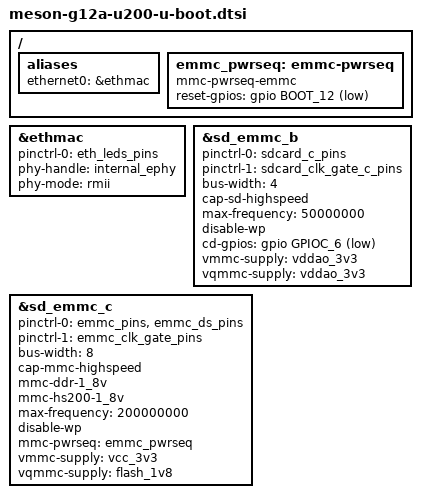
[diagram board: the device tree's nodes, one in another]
// SPDX-License-Identifier: (GPL-2.0+ OR MIT)
/*
 * Copyright (c) 2019 BayLibre, SAS.
 * Author: Neil Armstrong <narmstrong@baylibre.com>
 */

#include "meson-g12a-u-boot.dtsi"

 / {
	aliases {
		ethernet0 = &ethmac;
	};

	emmc_pwrseq: emmc-pwrseq {
		compatible = "mmc-pwrseq-emmc";
		reset-gpios = <&gpio BOOT_12 GPIO_ACTIVE_LOW>;
	};
};

&ethmac {
	status = "okay";
	pinctrl-0 = <&eth_leds_pins>;
	pinctrl-names = "default";
	phy-handle = <&internal_ephy>;
	phy-mode = "rmii";
};


/* SD card */
&sd_emmc_b {
	status = "okay";
	pinctrl-0 = <&sdcard_c_pins>;
	pinctrl-1 = <&sdcard_clk_gate_c_pins>;
	pinctrl-names = "default", "clk-gate";

	bus-width = <4>;
	cap-sd-highspeed;
	max-frequency = <50000000>;
	disable-wp;

	cd-gpios = <&gpio GPIOC_6 GPIO_ACTIVE_LOW>;
	vmmc-supply = <&vddao_3v3>;
	vqmmc-supply = <&vddao_3v3>;
};

/* eMMC */
&sd_emmc_c {
	status = "okay";
	pinctrl-0 = <&emmc_pins>, <&emmc_ds_pins>;
	pinctrl-1 = <&emmc_clk_gate_pins>;
	pinctrl-names = "default", "clk-gate";

	bus-width = <8>;
	cap-mmc-highspeed;
	mmc-ddr-1_8v;
	mmc-hs200-1_8v;
	max-frequency = <200000000>;
	disable-wp;

	mmc-pwrseq = <&emmc_pwrseq>;
	vmmc-supply = <&vcc_3v3>;
	vqmmc-supply = <&flash_1v8>;
};
